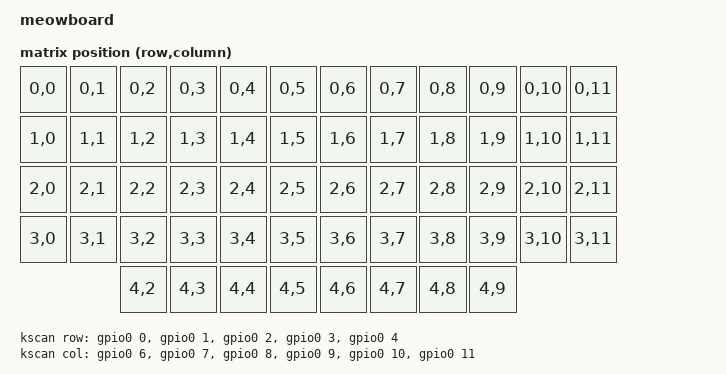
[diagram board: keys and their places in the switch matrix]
// This file was generated from a template. Edit it to match your keyboard.
// See https://docs.zephyrproject.org/3.5.0/hardware/porting/board_porting.html
// and https://zmk.dev/docs/development/hardware-integration/new-shield for more
// instructions.

#include <dt-bindings/zmk/matrix_transform.h>

#include "meowboard-layouts.dtsi"
#include <freq.h>

#include <zephyr/dt-bindings/i2c/i2c.h>
#include <zephyr/dt-bindings/pwm/pwm.h>

#include <zephyr/dt-bindings/pinctrl/rpi-pico-rp2350a-pinctrl.h>

/ {

        model = "meowboard";
        compatible = "meowboard";
        
        kscan: kscan {
            // If the hardware does not use a switch matrix, change this to the
            // appropriate driver and update the properties below to match.
            // See https://zmk.dev/docs/config/kscan for supported key scan drivers.
            compatible = "zmk,kscan-gpio-matrix";
            // Set this to "col2row" or "row2col" to match the hardware. If using
            // "row2col", change the col-gpios in the _left.overlay and _right.overlay
            // files to (GPIO_ACTIVE_HIGH | GPIO_PULL_DOWN) and the row-gpios here to
            // GPIO_ACTIVE_HIGH.
            diode-direction = "col2row";
            wakeup-source;
        
            // Replace these comments with the GPIO pins in the matrix.
            // See https://zmk.dev/docs/development/hardware-integration/new-shield#shield-overlays
            row-gpios
                = <&gpio0 0 (GPIO_ACTIVE_HIGH | GPIO_PULL_DOWN)>
                , <&gpio0 1 (GPIO_ACTIVE_HIGH | GPIO_PULL_DOWN)>
                , <&gpio0 2 (GPIO_ACTIVE_HIGH | GPIO_PULL_DOWN)>
                , <&gpio0 3 (GPIO_ACTIVE_HIGH | GPIO_PULL_DOWN)>
                , <&gpio0 4 (GPIO_ACTIVE_HIGH | GPIO_PULL_DOWN)>
                ;
            col-gpios
                = <&gpio0 6  GPIO_ACTIVE_HIGH>
                , <&gpio0 7  GPIO_ACTIVE_HIGH> 
                , <&gpio0 8  GPIO_ACTIVE_HIGH>
                , <&gpio0 9  GPIO_ACTIVE_HIGH>
                , <&gpio0 10  GPIO_ACTIVE_HIGH>
                , <&gpio0 11 GPIO_ACTIVE_HIGH>
                ;
        };
        
        default_transform: default_transform {
            // See https://zmk.dev/docs/development/hardware-integration/new-shield#matrix-transform
            // for how to configure this
            compatible = "zmk,matrix-transform";
            columns = <12>;
            rows = <5>;
        
            map = <
RC(0,0) RC(0,1) RC(0,2) RC(0,3) RC(0,4) RC(0,5)  RC(0,6) RC(0,7) RC(0,8) RC(0,9) RC(0,10) RC(0,11)
RC(1,0) RC(1,1) RC(1,2) RC(1,3) RC(1,4) RC(1,5)  RC(1,6) RC(1,7) RC(1,8) RC(1,9) RC(1,10) RC(1,11)
RC(2,0) RC(2,1) RC(2,2) RC(2,3) RC(2,4) RC(2,5)  RC(2,6) RC(2,7) RC(2,8) RC(2,9) RC(2,10) RC(2,11)
RC(3,0) RC(3,1) RC(3,2) RC(3,3) RC(3,4) RC(3,5)  RC(3,6) RC(3,7) RC(3,8) RC(3,9) RC(3,10) RC(3,11)
                RC(4,2) RC(4,3) RC(4,4) RC(4,5)  RC(4,6) RC(4,7) RC(4,8) RC(4,9)
            >;
        };
        wired_split {
                compatible = "zmk,wired-split";
                device = <&uart0>;
        };
	chosen {
		zephyr,sram = &sram0;
		zephyr,flash = &flash0;
		zephyr,console = &uart1;
		zephyr,shell-uart = &uart1;
		zephyr,code-partition = &code_partition;
                zmk,physical-layout = &default_layout;

	};

	aliases {
		watchdog0 = &wdt0;
	};
};

&flash0 {
	reg = <0x10000000 DT_SIZE_M(2)>;

	partitions {
		compatible = "fixed-partitions";
		#address-cells = <1>;
		#size-cells = <1>;

		/* Reserved memory for an image definition block. The block is much
		 * smaller than 256 bytes, but in practice the linker places the vector
		 * table at a much larger alignment offset.
		 */
		image_def: partition@0 {
			label = "image_def";
			reg = <0x00000000 0x100>;
			read-only;
		};

		/*
		 * Usable flash. Starts at 0x100, after the image definition block.
		 * The partition size is 4MB minus the 0x100 bytes taken by the
		 * image definition.
		 */
		code_partition: partition@100 {
			label = "code-partition";
			reg = <0x100 (DT_SIZE_M(2) - 0x100)>;
			read-only;
		};
	};
};

&uart0 {
	current-speed = <115200>;
	status = "okay";
	pinctrl-0 = <&uart0_default>;
	pinctrl-names = "default";
};
&uart1 {
	current-speed = <115200>;
	status = "okay";
	pinctrl-0 = <&uart1_default>;
	pinctrl-names = "default";
};

&gpio0 {
	status = "okay";
};

&spi0 {
	clock-frequency = <DT_FREQ_M(8)>;
	pinctrl-0 = <&spi0_default>;
	pinctrl-names = "default";
};

&i2c0 {
	clock-frequency = <I2C_BITRATE_STANDARD>;
	pinctrl-0 = <&i2c0_default>;
	pinctrl-names = "default";
	status = "okay";
};

&i2c1 {
	clock-frequency = <I2C_BITRATE_STANDARD>;
	pinctrl-0 = <&i2c1_default>;
	pinctrl-names = "default";
	status = "okay";
};

&adc {
	pinctrl-0 = <&adc_default>;
	pinctrl-names = "default";
	status = "okay";
};

&pwm {
	pinctrl-0 = <&pwm_ch4b_default>;
	pinctrl-names = "default";
	divider-int-0 = <255>;
};

&timer0 {
	status = "okay";
};

zephyr_udc0: &usbd {
	status = "okay";
};

pico_serial: &uart0 {};

&pinctrl {
	uart0_default: uart0_default {
		group1 {
			pinmux = <UART0_TX_P16>;
		};
		group2 {
			pinmux = <UART0_RX_P17>;
			input-enable;
		};
	};
        uart1_default: uart1_default {
                group1 {
                        pinmux = <UART1_TX_P20>;
                };
                group2 {
                        pinmux = <UART1_RX_P21>;
                        input-enable;
                };
        };

	i2c0_default: i2c0_default {
		group1 {
			pinmux = <I2C0_SDA_P4>, <I2C0_SCL_P5>;
			input-enable;
			input-schmitt-enable;
		};
	};

	i2c1_default: i2c1_default {
		group1 {
			pinmux = <I2C1_SDA_P6>, <I2C1_SCL_P7>;
			input-enable;
			input-schmitt-enable;
		};
	};

	spi0_default: spi0_default {
		group1 {
			pinmux = <SPI0_CSN_P17>, <SPI0_SCK_P18>, <SPI0_TX_P19>;
		};
		group2 {
			pinmux = <SPI0_RX_P16>;
			input-enable;
		};
	};

	pwm_ch4b_default: pwm_ch4b_default {
		group1 {
			pinmux = <PWM_4B_P25>;
		};
	};

	adc_default: adc_default {
		group1 {
			pinmux = <ADC_CH0_P26>, <ADC_CH1_P27>, <ADC_CH2_P28>, <ADC_CH3_P29>;
			input-enable;
		};
	};
};


